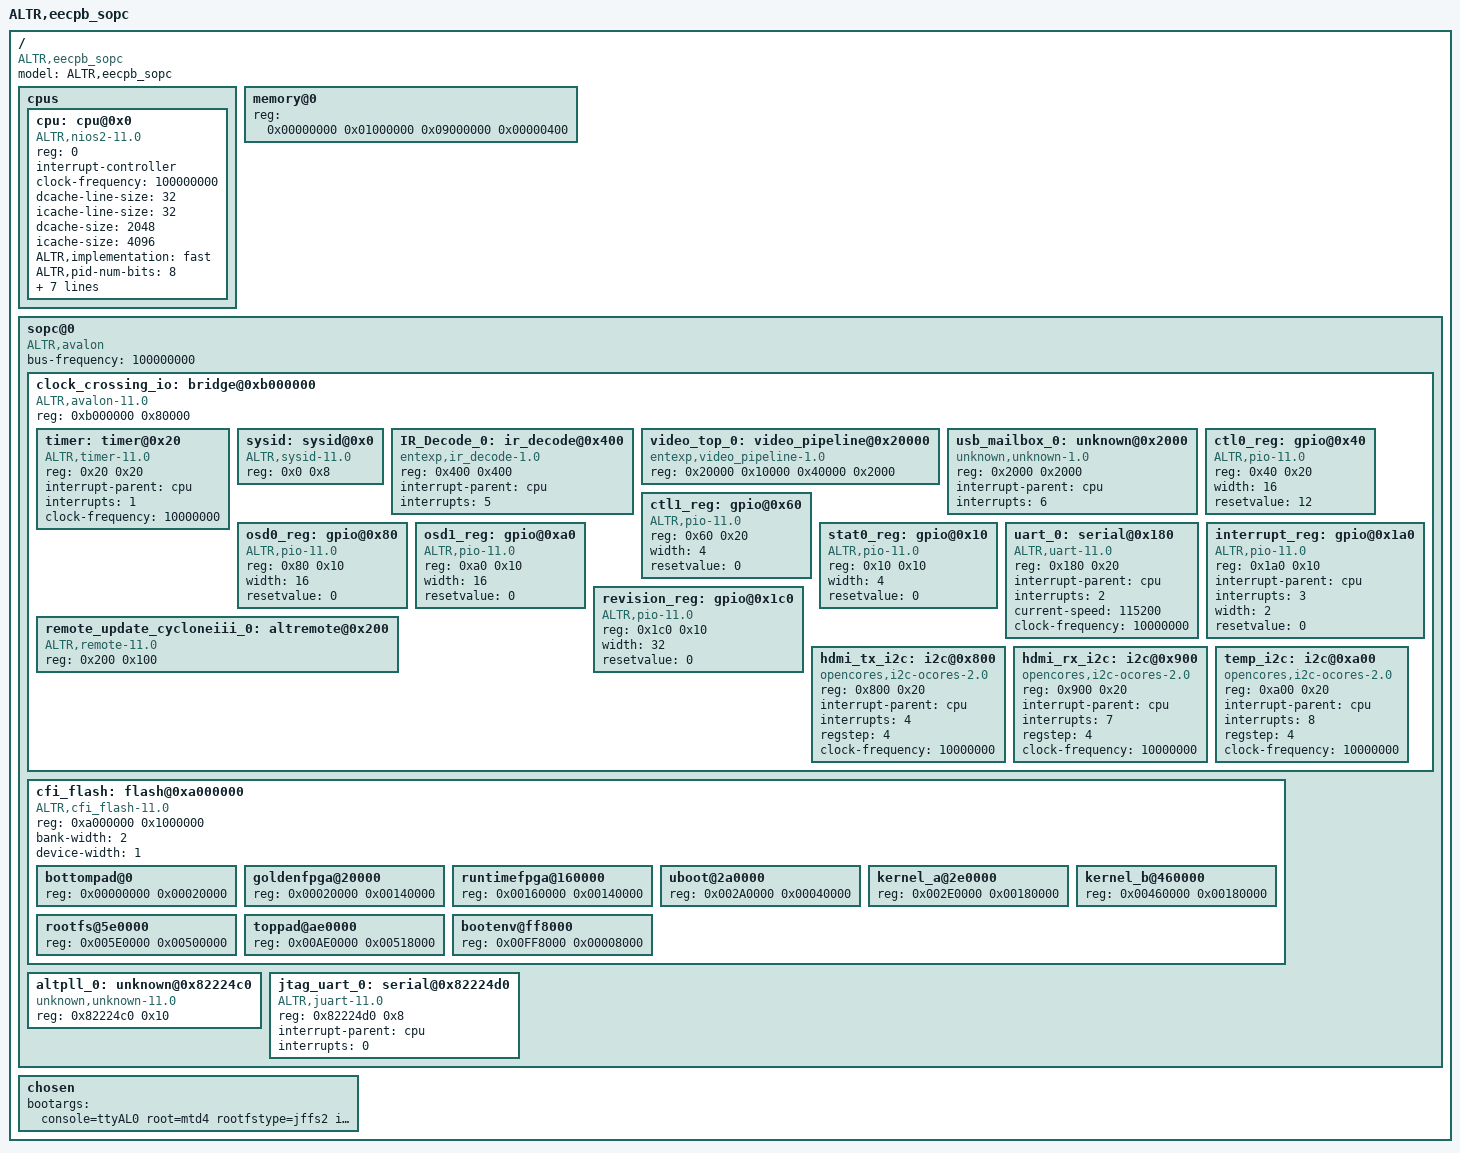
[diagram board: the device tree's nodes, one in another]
/*
 * This devicetree is generated by sopc2dts
 * Sopc2dts is written by Walter Goossens <waltergoossens@home.nl>
 * in cooperation with the nios2 community <Nios2-dev@sopc.et.ntust.edu.tw>
 */
/dts-v1/;
/ {
	model = "ALTR,eecpb_sopc";
	compatible = "ALTR,eecpb_sopc";
	#address-cells = <1>;
	#size-cells = <1>;
	cpus {
		#address-cells = <1>;
		#size-cells = <0>;
		cpu: cpu@0x0 {
			device_type = "cpu";
			compatible = "ALTR,nios2-11.0";
			reg = <0>;
			interrupt-controller;
			#interrupt-cells = <1>;
			clock-frequency = <100000000>;	//embeddedsw.CMacro.CPU_FREQ type NUMBER
			dcache-line-size = <32>;	//embeddedsw.CMacro.DCACHE_LINE_SIZE type NUMBER
			icache-line-size = <32>;	//embeddedsw.CMacro.ICACHE_LINE_SIZE type NUMBER
			dcache-size = <2048>;	//embeddedsw.CMacro.DCACHE_SIZE type NUMBER
			icache-size = <4096>;	//embeddedsw.CMacro.ICACHE_SIZE type NUMBER
			ALTR,implementation = "fast";	//embeddedsw.CMacro.CPU_IMPLEMENTATION type STRING
			ALTR,pid-num-bits = <8>;	//embeddedsw.CMacro.PROCESS_ID_NUM_BITS type NUMBER
			ALTR,tlb-num-ways = <16>;	//embeddedsw.CMacro.TLB_NUM_WAYS type NUMBER
			ALTR,tlb-num-entries = <256>;	//embeddedsw.CMacro.TLB_NUM_ENTRIES type NUMBER
			ALTR,tlb-ptr-sz = <8>;	//embeddedsw.CMacro.TLB_PTR_SZ type NUMBER
			ALTR,has-mul;	//embeddedsw.CMacro.HARDWARE_MULTIPLY_PRESENT type NUMBER
			ALTR,reset-addr = <0xca2a0000>;	//embeddedsw.CMacro.RESET_ADDR type NUMBER
			ALTR,fast-tlb-miss-addr = <0xc9000000>;	//embeddedsw.CMacro.FAST_TLB_MISS_EXCEPTION_ADDR type NUMBER
			ALTR,exception-addr = <0xc0000020>;	//embeddedsw.CMacro.EXCEPTION_ADDR type NUMBER
		};
	};
	memory@0 {
		device_type = "memory";
		reg = <0x00000000 0x01000000
			0x09000000 0x00000400>;
	};
	sopc@0 {
		ranges ;
		#address-cells = <1>;
		#size-cells = <1>;
		device_type = "soc";
		compatible = "ALTR,avalon","simple-bus";
		bus-frequency = < 100000000 >;
		//Port instruction_master of cpu
		clock_crossing_io: bridge@0xb000000 {
			compatible = "ALTR,avalon-11.0","simple-bus";
			reg = < 0xb000000 0x80000>;
			#address-cells = <1>;
			#size-cells = <1>;
			ranges = <0x00000020 0x0B000020 0x00000020
				0x00000000 0x0B000000 0x00000008
				0x00000400 0x0B000400 0x00000400
				0x00020000 0x0B020000 0x00010000
				0x00040000 0x0B040000 0x00002000
				0x00002000 0x0B002000 0x00002000
				0x00000040 0x0B000040 0x00000020
				0x00000060 0x0B000060 0x00000020
				0x00000080 0x0B000080 0x00000010
				0x000000A0 0x0B0000A0 0x00000010
				0x00000010 0x0B000010 0x00000010
				0x00000180 0x0B000180 0x00000020
				0x00000200 0x0B000200 0x00000100
				0x000001A0 0x0B0001A0 0x00000010
				0x000001C0 0x0B0001C0 0x00000010
				0x00000800 0x0B000800 0x00000020
				0x00000900 0x0B000900 0x00000020
				0x00000A00 0x0B000A00 0x00000020>;

			//Port m1 of clock_crossing_io
			timer: timer@0x20 {
				compatible = "ALTR,timer-11.0","ALTR,timer-1.0";
				reg = < 0x20 0x20>;
				interrupt-parent = < &cpu >;
				interrupts = < 1 >;
				clock-frequency = <10000000>;
			}; //end timer (timer)

			sysid: sysid@0x0 {
				compatible = "ALTR,sysid-11.0","ALTR,sysid-1.0";
				reg = < 0x0 0x8>;
			}; //end sysid (sysid)

			IR_Decode_0: ir_decode@0x400 {
				compatible = "entexp,ir_decode-1.0";
				reg = < 0x400 0x400>;
				interrupt-parent = < &cpu >;
				interrupts = < 5 >;
			}; //end ir_decode (IR_Decode_0)

			video_top_0: video_pipeline@0x20000 {
				compatible = "entexp,video_pipeline-1.0";
				reg = < 0x20000 0x10000 0x40000 0x2000>;
			}; //end video_pipeline (video_top_0)

			usb_mailbox_0: unknown@0x2000 {
				compatible = "unknown,unknown-1.0";
				reg = < 0x2000 0x2000>;
				interrupt-parent = < &cpu >;
				interrupts = < 6 >;
			}; //end unknown (usb_mailbox_0)

			ctl0_reg: gpio@0x40 {
				compatible = "ALTR,pio-11.0","ALTR,pio-1.0";
				reg = < 0x40 0x20>;
				width = <16>;	//width type NUMBER
				resetvalue = <12>;	//resetValue type NUMBER
			}; //end gpio (ctl0_reg)

			ctl1_reg: gpio@0x60 {
				compatible = "ALTR,pio-11.0","ALTR,pio-1.0";
				reg = < 0x60 0x20>;
				width = <4>;	//width type NUMBER
				resetvalue = <0>;	//resetValue type NUMBER
			}; //end gpio (ctl1_reg)

			osd0_reg: gpio@0x80 {
				compatible = "ALTR,pio-11.0","ALTR,pio-1.0";
				reg = < 0x80 0x10>;
				width = <16>;	//width type NUMBER
				resetvalue = <0>;	//resetValue type NUMBER
			}; //end gpio (osd0_reg)

			osd1_reg: gpio@0xa0 {
				compatible = "ALTR,pio-11.0","ALTR,pio-1.0";
				reg = < 0xa0 0x10>;
				width = <16>;	//width type NUMBER
				resetvalue = <0>;	//resetValue type NUMBER
			}; //end gpio (osd1_reg)

			stat0_reg: gpio@0x10 {
				compatible = "ALTR,pio-11.0","ALTR,pio-1.0";
				reg = < 0x10 0x10>;
				width = <4>;	//width type NUMBER
				resetvalue = <0>;	//resetValue type NUMBER
			}; //end gpio (stat0_reg)

			uart_0: serial@0x180 {
				compatible = "ALTR,uart-11.0","ALTR,uart-1.0";
				reg = < 0x180 0x20>;
				interrupt-parent = < &cpu >;
				interrupts = < 2 >;
				current-speed = <115200>;	//embeddedsw.CMacro.BAUD type NUMBER
				clock-frequency = <10000000>;	//embeddedsw.CMacro.FREQ type NUMBER
			}; //end serial (uart_0)

			remote_update_cycloneiii_0: altremote@0x200 {
				compatible = "ALTR,remote-11.0","ALTR,remote-1.0";
				reg = < 0x200 0x100>;
			}; //end altremote (remote_update_cycloneiii_0)

			interrupt_reg: gpio@0x1a0 {
				compatible = "ALTR,pio-11.0","ALTR,pio-1.0";
				reg = < 0x1a0 0x10>;
				interrupt-parent = < &cpu >;
				interrupts = < 3 >;
				width = <2>;	//width type NUMBER
				resetvalue = <0>;	//resetValue type NUMBER
			}; //end gpio (interrupt_reg)

			revision_reg: gpio@0x1c0 {
				compatible = "ALTR,pio-11.0","ALTR,pio-1.0";
				reg = < 0x1c0 0x10>;
				width = <32>;	//width type NUMBER
				resetvalue = <0>;	//resetValue type NUMBER
			}; //end gpio (revision_reg)

			hdmi_tx_i2c: i2c@0x800 {
				compatible = "opencores,i2c-ocores-2.0","opencores,i2c-ocores";
				reg = < 0x800 0x20>;
				interrupt-parent = < &cpu >;
				interrupts = < 4 >;
				regstep = <4>;
				clock-frequency = <10000000>;
			}; //end i2c (hdmi_tx_i2c)

			hdmi_rx_i2c: i2c@0x900 {
				compatible = "opencores,i2c-ocores-2.0","opencores,i2c-ocores";
				reg = < 0x900 0x20>;
				interrupt-parent = < &cpu >;
				interrupts = < 7 >;
				regstep = <4>;
				clock-frequency = <10000000>;
			}; //end i2c (hdmi_rx_i2c)

			temp_i2c: i2c@0xa00 {
				compatible = "opencores,i2c-ocores-2.0","opencores,i2c-ocores";
				reg = < 0xa00 0x20>;
				interrupt-parent = < &cpu >;
				interrupts = < 8 >;
				regstep = <4>;
				clock-frequency = <10000000>;
			}; //end i2c (temp_i2c)

		}; //end bridge (clock_crossing_io)

		cfi_flash: flash@0xa000000 {
			#address-cells = <1>;
			#size-cells = <1>;
			compatible = "ALTR,cfi_flash-11.0","cfi-flash";
			reg = < 0xa000000 0x1000000>;
			bank-width = <2>;
			device-width = <1>;
			bottompad@0 {
				reg = < 0x00000000 0x00020000 >;
			};
			goldenfpga@20000 {
				reg = < 0x00020000 0x00140000 >;
			};
			runtimefpga@160000 {
				reg = < 0x00160000 0x00140000 >;
			};
			uboot@2a0000 {
				reg = < 0x002A0000 0x00040000 >;
			};
			kernel_a@2e0000 {
				reg = < 0x002E0000 0x00180000 >;
			};
			kernel_b@460000 {
				reg = < 0x00460000 0x00180000 >;
			};
			rootfs@5e0000 {
				reg = < 0x005E0000 0x00500000 >;
			};
			toppad@ae0000 {
				reg = < 0x00AE0000 0x00518000 >;
			};
			bootenv@ff8000 {
				reg = < 0x00FF8000 0x00008000 >;
			};
		}; //end flash (cfi_flash)

		//Port tightly_coupled_instruction_master_0 of cpu
		//Port data_master of cpu
		altpll_0: unknown@0x82224c0 {
			compatible = "unknown,unknown-11.0";
			reg = < 0x82224c0 0x10>;
		}; //end unknown (altpll_0)

		jtag_uart_0: serial@0x82224d0 {
			compatible = "ALTR,juart-11.0","ALTR,juart-1.0";
			reg = < 0x82224d0 0x8>;
			interrupt-parent = < &cpu >;
			interrupts = < 0 >;
		}; //end serial (jtag_uart_0)

		//Port tightly_coupled_data_master_0 of cpu
	}; //sopc
	chosen {
		bootargs = "console=ttyAL0 root=mtd4 rootfstype=jffs2 init=/bin/init";
	};
};
